# pse84 register map
Vendor: Cypress Semiconductor; Series: PSE84; File version: 1.0
CPU: CM33 r0p1, little endian, MPU, FPU, VTOR, 3 interrupt priority bits
Registers are 32-bit, read-write, reset 0x0 unless marked. A register's access mark holds for its fields unless they carry their own. Offsets are from the block's base; [hi:lo] are bit positions; lines under a group give offsets from that group; {n}, {i} and the like mark numbered series; 'fields as' and 'values as' point back to an identical list; <NAME> marks a mode.

## SMIF0 (part 3 of 4) — SMIF subsystem (bridge + 2 core SMIFs, OR no bridge and 1 core SMIF)
Base 0x44400000
{0x20000+0x20000*i} CORE[{i}] (i=0..1) group — Serial Memory Interface
  {0x800+0x80*j} DEVICE[{j}] (j=0..3) group — Device (only used for XIP acceses)
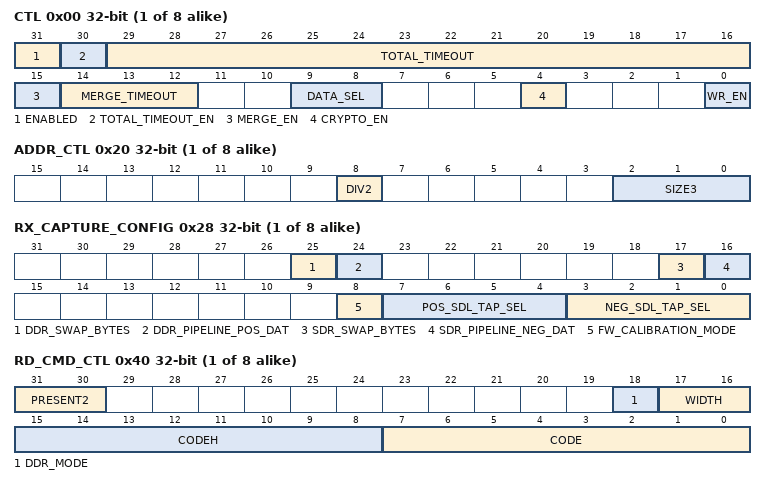
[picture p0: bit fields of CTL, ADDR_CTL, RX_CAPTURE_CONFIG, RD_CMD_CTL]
    0x00 CTL — Control
      [31] ENABLED — Device enable: '0': Disabled. '1': Enabled.
      [30] TOTAL_TIMEOUT_EN — Total transfer timeout enable. '0': Disabled. There is no limit for the total transfer time. The continuous transfer merge timeout for limiting the idle time of the memory interface still applies. '1': Enabled. The maximum total transfer time is limited by field TOTAL_TIMEOUT.
      [29:16] TOTAL_TIMEOUT — Total transfer timeout in clk_mem cycles. The counting of the total timout period is done in the XIP block using clk_mem cycles. It starts when the first command of a new (not merged) transaction is transferred to the TX command FIFO causing the interface logic to select the memory. After this period the memory device is deselected. This feature is needed for RAM devices requiring refresh cycles. The value needs to be derived from the RAMs maximum transaction length time (tCMS) minus the time of transferring 2x16byte data block (data granularity of the XIP ports is 16byte, 1 16byte block transfer outstanding, another available for merging). If the result in negative, MERGE_EN must be set to '0'. Example: RAM device tCMS = 4us, interface clock frequency = 100MHz: total transfer timeout is 4us - 2x16x10ns = 3680ns. With clk_mem frequency of 200MHz the TOTAL_TIMEOUT value is 3680/5 = 736. Note: In the unlikely case that the total transfer timeout is used (usually for RAM devices) while the page boundary crossing latency generation is enabled via RD_BOUND_CTL.PRESENT (usually for FLASH devices) the additional time needs to taken into account.
      [15] MERGE_EN — Continous transfer merge enable: '0': Disabled. No merging of transfers is done. Longest possible memory transfer is 16 Byte. '1': Enabled. Merging of continous transfers is done. This skips the overhead (command, address, mode, dummy cycles) for a continuous (linear sequential) transfer.
      [14:12] MERGE_TIMEOUT — Continuous transfer merge timeout in clk_mem cycles. This limits the standby time of the memory interface, i.e. the time the memory device is selected but no data is transferred. The counting of the merge timeout period is done in the XIP block using clk_mem cycles. It starts when the last TX or RX byte is transferred to or from the data FIFOs. After this period the memory device is deselected. A later transfer, even from a continuous address, starts with the overhead phases (command, address, mode, dummy cycles).
        0=_1_cycle (Timeout after 1 clk_mem cycle. That means transfers will only be merged if the continuous transfer request is already available when the previous transfer is finished.); 1=_16_cycles (Timeout after 2^4 = 16 clk_mem cycles. At a clk_mem frequency of 200MHz this means 80ns.); 2=_256_cycles (Timeout after 2^8 = 256 clk_mem cycles. At a clk_mem frequency of 200MHz this means ~1.3us.); 3=_4096_cycles (Timeout after 2^12 = 4096 clk_mem cycles. At a clk_mem frequency of 200MHz this means ~20us.); 4=_65536_cycles (Timeout after 2^16 = 65536 clk_mem cycles. At a clk_mem frequency of 200MHz this means ~330us.); 5=RSVD5 (N/A); 6=RSVD6 (N/A); 7=RSVD7 (N/A)
      [9:8] DATA_SEL — Specifies the connection of the IP's data lines (spi_data[0], ..., spi_data[7]) to the device's data lines (SI/IO0, SO/IO1, IO2, IO3, IO4, IO5, IO6, IO7): '0': spi_data[0] = IO0, spi_data[1] = IO1, ..., spi_data[7] = IO7. This value is allowed for single, dual, quad, dual quad and octal SPI modes. This value must be used for the first device in dual quad SPI mode. This value must be used for octal SPI mode. '1': spi_data[2] = IO0, spi_data[3] = IO1. This value is only allowed for single and dual SPI modes. '2': spi_data[4] = IO0, spi_data[5] = IO1, ..., spi_data[7] = IO3. This value is only allowed for single, dual, quad and dual quad SPI modes. In dual quad SPI mode, this value must be used for the second device. '3': spi_data[6] = IO0, spi_data[7] = IO1. This value is only allowed for single and dual SPI modes.
      [4] CRYPTO_EN — Cryptography on read/write accesses: '0': disabled. '1': enabled. This register should not be changed dynamically. Conditions 1. The same CRYPTO_EN setting should be used when a memory is read back after a write. 2. CRYPTO_EN should not be changed while IP is busy.
      [0] WR_EN — Write enable: '0': write transfers are not allowed to this device. An attempt to write to this device results in an AHB-Lite bus error. '1': write transfers are allowed to this device.
    0x08 ADDR reset not defined — Device region base address
      [31:8] ADDR — Specifies the base address of the device region. If the device region is 2^m Bytes, ADDR MUST be a multiple of 2^m. In dual quad SPI data transfer, the two devices should have the same ADDR and MASK register settings. The device control information (ADDR_CTL, RD_CMD_CTL, etc.) are provided by the MMIO control registers of the device with the lowest index. The most significant bit fields are constants and set based on the SMIF_XIP_ADDR parameter. The most significant bits are identified on the SMIF_XIP_MASK parameter. E.g., if SMIF_XIP_MASK is 0xff00:0000 (16 MB XIP memory region), ADDR[31:24] = SMIF_XIP_ADDR[31:24].
    0x0C MASK reset not defined — Device region mask
      [31:8] MASK — Specifies the size of the device region. All '1' bits are used to compare the incoming transfer request address A[31:0] with the address as specified in ADDR.ADDR: Address A is in the device when (A[31:8] & MASK[31:8]) == ADDR.ADDR[31:8]. The most significant bit fields are constants and set to'1'. The most significant bits are identified on the SMIF_XIP_MASK parameter. E.g., if SMIF_XIP_MASK is 0xff00:0000 (16 MB XIP memory region), MASK[31:24] = 0xff. Note: a transfer request that is not in any device region results in an AHB-Lite bus error.
    0x20 ADDR_CTL — Address control
      [8] DIV2 — Specifies if the AHB-Lite bus transfer address is divided by 2 or not: '0': No divide by 2. '1': Divide by 2. This functionality is used for read and write operation in XIP, dual quad SPI mode; i.e. this DIV2 must be set to '1' in dual quad SPI mode. If DIV2 is set to '1', the memory does not support write masking (WR_DUMMY_CTL.RWDS_EN = '0'), and in this configuration a write transfer is requested and the write transfer request address is NOT a multiple of 2 or the requested number of Bytes to be written is not a multiple of 2, the XIP_ALIGNMENT_ERROR interrupt cause is activated.
      [2:0] SIZE3
    0x28 RX_CAPTURE_CONFIG — RX capture configuration
      [25] DDR_SWAP_BYTES — 0: Does not swap DDR receive data captured relative to the negedge of the receive clock with the data captured relative to the posedge of the receive clock 1: Does swap The setting DDR_SWAP_BYTES is ignored and operates as if set to 1 (even if set to 0) when CORE.CTL2.RX_CAPTURE_MODE=2
      [24] DDR_PIPELINE_POS_DAT — 0: Does not pipeline DDR receive data captured relative to the posedge of the receive clock 1: Does pipeline DDR_PIPELINE_POS_DAT must be set to '1' if CORE.CTL2.RX_CAPTURE_MODE=2
      [17] SDR_SWAP_BYTES — 0: Does not swap SDR receive data captured relative to the negedge of the receive clock with the data captured relative to the posedge of the receive clock 1: Does swap
      [16] SDR_PIPELINE_NEG_DAT — 0: Does not pipeline SDR receive data captured relative to the negedge of the receive clock 1: Does pipeline
      [8] FW_CALIBRATION_MODE — 0: Disabled 1: Enabled Hyperbus / xSPI / Octal SPI w/DQS and Software De-skewing Mode based on register HB FW Calibration tap sel0/1
      [7:4] POS_SDL_TAP_SEL — Same as NEG_SDL_TAP_SEL except for the 'pos' SDL.
      [3:0] NEG_SDL_TAP_SEL — Determines the amount of delay through the 'neg' SDL for the receive clock coming from the pins in terms of the number of tap delays. There are 16 SDL taps and the delay resolution of each tap is controlled by and thus closely mimics the delay resolution of the MDL. i.e., each tap has a resolution roughly equal to 1/16th of the DLL reference clock period. Setting 0 constitutes 1 tap delay, setting 1 constitutes 2 tap delays, etc., setting 15 constitutes 16 tap delays (effectively a full DLL reference clock period).
    0x30 RD_STATUS ro — Read status
      [7:0] FS_STATUS — Provides the Functional Safety Status Register of the memory received with the last read transfer.
    0x40 RD_CMD_CTL — Read command control
      [31:30] PRESENT2 — Presence of command field: '0': not present '1': present (1 Byte) '2': present (2 Byte for OPI) Note: For octal data transfer with DDR mode (WIDTH='3' and DDR_MODE='1') either the HB protocol needs to be selected (by ADDR_CTL.SIZE3='7') or this field needs to be set to PRESENT2='2'.
      [18] DDR_MODE — Mode of transfer rate: '0': SDR mode '1': DDR mode
      [17:16] WIDTH — Width of data transfer: '0': 1 bit/cycle (single data transfer). '1': 2 bits/cycle (dual data transfer). '2': 4 bits/cycle (quad data transfer). '3': 8 bits/cycle (octal data transfer).
      [15:8] CODEH — Command high byte code. This field specifies the most significant command byte, sent before the least significant command byte (CODE). It is only used when PRESENT2 = '2'.
      [7:0] CODE — Command byte code.
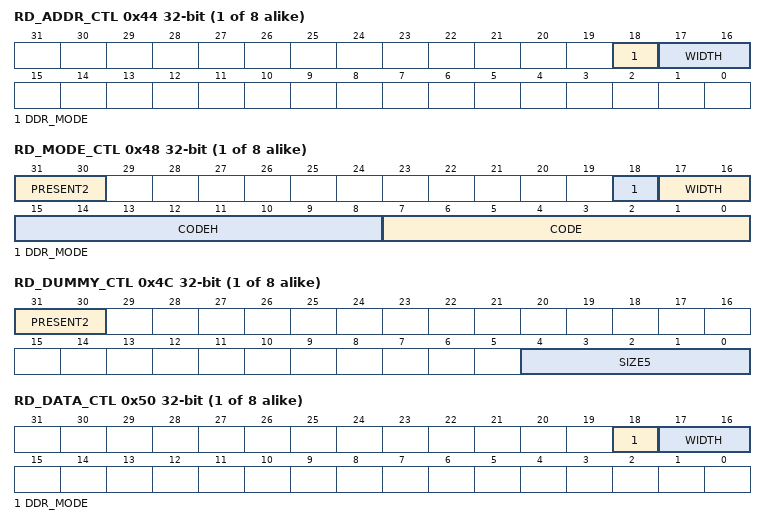
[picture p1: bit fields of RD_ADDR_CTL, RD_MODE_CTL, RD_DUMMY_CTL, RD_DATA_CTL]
    0x44 RD_ADDR_CTL — Read address control
      [18] DDR_MODE — Mode of transfer rate.
      [17:16] WIDTH — Width of transfer.
    0x48 RD_MODE_CTL — Read mode control
      [31:30] PRESENT2 — Presence of mode field: '0': not present '1': present (1 Byte) '2': present (2 Byte for OPI) Note: For octal data transfer with DDR mode (WIDTH='3' and DDR_MODE='1') this field needs to be set to PRESENT2='2' to generate a mode field (or to PRESENT2='0').
      [18] DDR_MODE — Mode of transfer rate.
      [17:16] WIDTH — Width of transfer.
      [15:8] CODEH — Mode high byte code. This field specifies the most significant mode byte, sent before the least significant mode byte (CODE). It is only used when PRESENT2 = '2'.
      [7:0] CODE — Mode byte code. Note: If a mode field is present (PRESENT='1') for octal data transfer with DDR mode (WIDTH='3' and DDR_MODE='1') the CODE is sent twice.
    0x4C RD_DUMMY_CTL — Read dummy control
      [31:30] PRESENT2 — Presence of dummy cycles: '0': not present '1': present '2': present - Dummy cycles are doubled when RWDS refresh indicator is high during CA cycle. (HyperRAM variable latency mode) Notes: - If transmitting command, address and mode fields in SDR mode (driving data between falling edges of spihb_clk_out) and the memory is driving read data in DDR mode (based on memory type and transmitted command), then there must be at least 1 latency / dummy cycle specified (RD_DUMMY_CTL.PRESENT2 > 0') to prevent controller and memory driving data signals at the same time. The same is true for the theoretical (practically irrelevant case) of transmitting at least one of the command, address and mode fields in DDR mode but receiving data from the memory in SDR mode. - When using the RWDS / DQS based capturing scheme (CTL2.RX_CAPTURE_MODE = 2), then there is a minimum number of latency / dummy cycles required (RD_DUMMY_CTL.PRESENT2 > 0). For the Hyperbus protocol (DDR_CTL.SIZE3=7) at least 1 latency / dummy cycle has to be specified, for SPI with DQS capturing at least 2 latency / dummy cycles need to be selected (RD_DUMMY_CTL.SIZE5 > 0, exception see following note). - In case of falling edge RWDS / DQS capturing (CTL2.RX_CAPTURE_MODE = 2) and SDR mode, SW should reduce the number of dummy cycles by 1 compared to the latency cycles required by the memory device. -DDR read commands need at least one dummy cycle -For Hyperbus, set RD DUMMY_CTL.SIZE5=initial latency cycles-2
      [4:0] SIZE5 — Number of dummy cycles (minus 1): '0': 1 cycles ... '31': 32 cycles. Note: this field specifies dummy cycles, not dummy Bytes!
    0x50 RD_DATA_CTL — Read data control
      fields as CORE[0].DEVICE[0].RD_ADDR_CTL
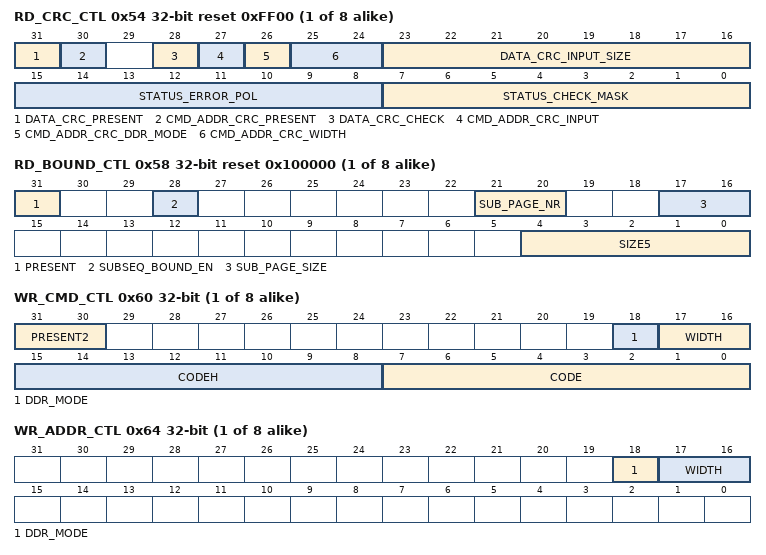
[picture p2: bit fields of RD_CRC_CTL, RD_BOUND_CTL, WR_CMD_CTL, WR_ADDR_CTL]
    0x54 RD_CRC_CTL reset 0xFF00 — Read Bus CRC control
      [31] DATA_CRC_PRESENT — Presence of data CRC field: '0': not present '1': present Note: Width and data transfer mode (SDR or DDR) of read data CRC fields are the same as for the associated read data fields, i.e. are specified by RD_DATA_CTL.WIDTH and RD_DATA_CTL.DDR_MODE.
      [30] CMD_ADDR_CRC_PRESENT — Presence of command / address CRC field: '0': not present '1': present Note: For octal data transfer with DDR mode (RD_CRC_CTL.WIDTH='3' and RD_CRC_CTL.DDR_MODE='1') the command / address CRC byte is sent twice, otherwise the command / address CRC byte is only sent once.
      [28] DATA_CRC_CHECK
      [27] CMD_ADDR_CRC_INPUT — Specifies which fields are included in the command / address CRC generation. '0': The command / address CRC field is generated over the address and (if present) mode fields only. '1': The command / address CRC field is generated over the command, address and (if present) mode fields.
      [26] CMD_ADDR_CRC_DDR_MODE — Mode of transfer rate of command / address CRC field.
      [25:24] CMD_ADDR_CRC_WIDTH — Width of command / address CRC field.
      [23:16] DATA_CRC_INPUT_SIZE — Number of input data bytes for CRC generation (minus 1), i.e. number of data bytes over which the data CRC field is generated (minus 1): '0': 1 byte ... '255': 256 bytes. Note: For octal data transfer with DDR mode (RD_DATA_CTL.WIDTH='3' and RD_DATA_CTL.DDR_MODE='1') the number of bytes for CRC generation must be even (i.e. DATA_CRC_INPUT_SIZE must be odd).
      [15:8] STATUS_ERROR_POL — Specifies the polarity of the Functional Safety Status field bits. There is 1 polarity bit for each Functional Safety Status bit. '0': The associated Functional Safety Status bit is active-low. '1': The associated Functional Safety Status bit is active-high.
      [7:0] STATUS_CHECK_MASK — Specifies which of the Functional Safety Status field bits are checked. There is 1 mask bit for each Functional Safety Status bit. '0': The associated Functional Safety Status bit is not checked. '1': The associated Functional Safety Status bit is checked. If the received Funciontal Safety Status bit = Functional Safety Status Error Polarity (STATUS_ERROR_POLARITY), then a Functional Safety Status error interrupt and a XIP bus error response is generated.
    0x58 RD_BOUND_CTL reset 0x100000 — Read boundary control
      [31] PRESENT — Presence of first page boundary latency cycles: '0': not present '1': present
      [28] SUBSEQ_BOUND_EN — Enable subsequent page boundary latency cycles. '0': Disabled. The page crossing latency cycles are only generated when crossing the first page boundary (i.e. the first time when the SUB_PAGE_NRth sub page boundary is crossed, e.g. with 2 sub pages per page when the 2nd sub page boundary is crossed). '1': Enabled. The page crossing latency cycles are generated when crossing the first and subsequent page boundaries (i.e. every time when a SUB_PAGE_NRth sub page boundary is crossed, e.g. with 2 sub pages per page when the 2nd, 4th, 6th, ... sub page boundary is crossed). Note: This only applies when the number of base latency cycles (SIZE5+1) is greater than the size of a page (base_latency > page_size). Must be set to 0 otherwise.
      [21:20] SUB_PAGE_NR — Specifies the number of sub pages per page. '0': 1 sub pages per page, i.e. page_size = sub_page_size '1': 2 sub pages per page, i.e. page_size = 2 x sub_page_size '2': 4 sub pages per page, i.e. page_size = 4 x sub_page_size '3': 8 sub pages per page, i.e. page_size = 8 x sub_page_size
      [17:16] SUB_PAGE_SIZE — Specifies the size of a memory sub page 'sub_page_size'. '0': sub_page_size = 8 words = 16 bytes (default). '1': sub_page_size = 16 words = 32 bytes. '2': sub_page_size = 32 words = 64 bytes. '3': sub_page_size = 64 words = 128 bytes.
      [4:0] SIZE5 — Number of base latency cycles (minus 1) used for calculating the number of fist page boundary crossing latency cycles: '0': base_latency = 1 cycles ... '31': base_latency = 32 cycles. The actual latency cycles when crossing the first page boundary depend on the start address of the transaction and is calculated as follows: if ((page_size - base_latency) < Start_Addr & (sub_page_size - 1)) { ((Start_Addr & (sub_page_size - 1)) - page_size + base_latency) } else { 0 }
    0x60 WR_CMD_CTL — Write command control
      [31:30] PRESENT2 — Presence of command field: '0': not present '1': present (1 Byte) '2': present (2 Byte for OPI) Note: For octal data transfer with DDR mode (WIDTH='3' and DDR_MODE='1') either the HB protocol needs to be selected (by ADDR_CTL.SIZE3='7') or this field needs to be set to PRESENT2='2'.
      [18] DDR_MODE — Mode of transfer rate.
      [17:16] WIDTH — Width of transfer.
      [15:8] CODEH — Command high byte code. This field specifies the most significant command byte, sent before the least significant command byte (CODE). It is only used when PRESENT2 = '2'.
      [7:0] CODE — Command byte code.
    0x64 WR_ADDR_CTL — Write address control
      fields as CORE[0].DEVICE[0].RD_ADDR_CTL
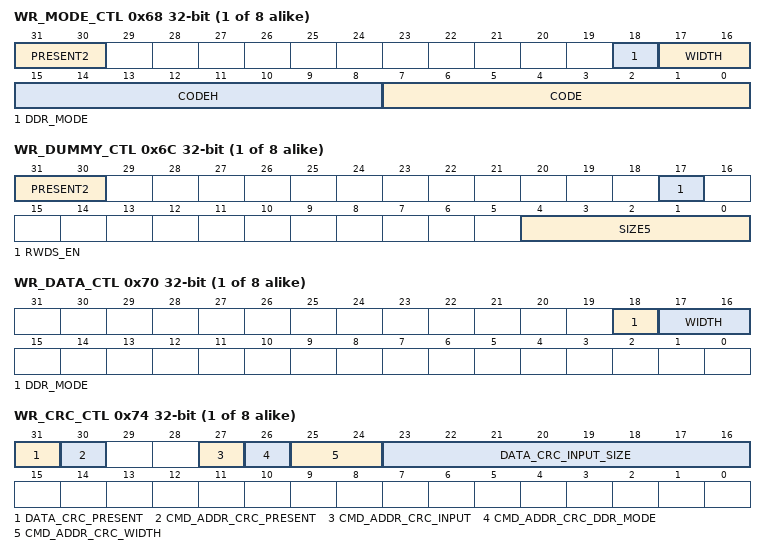
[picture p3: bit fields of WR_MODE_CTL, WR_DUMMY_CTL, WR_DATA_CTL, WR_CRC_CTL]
    0x68 WR_MODE_CTL — Write mode control
      [31:30] PRESENT2 — Presence of mode field: '0': not present '1': present (1 Byte) '2': present (2 Byte for OPI) Note: For octal data transfer with DDR mode (WIDTH='3' and DDR_MODE='1') this field needs to be set to PRESENT2='2' to generate a mode field (or to PRESENT2='0').
      [18] DDR_MODE — Mode of transfer rate.
      [17:16] WIDTH — Width of transfer.
      [15:8] CODEH — Mode high byte code. This field specifies the most significant mode byte, sent before the least significant mode byte (CODE). It is only used when PRESENT2 = '2'.
      [7:0] CODE — Mode byte code.
    0x6C WR_DUMMY_CTL — Write dummy control
      [31:30] PRESENT2 — Presence of dummy cycles: '0': not present '1': present '2': present - Dummy cycles are doubled when RWDS refresh indicator is high during CA cycle. (HyperRAM variable latency mode)
      [17] RWDS_EN — Read-Write-Data-Strobe Enable. Specifies whether the RWDS output signal should be driven starting in the last dummy cycle until DESELECT. This is needed for write transactions with byte masking via RWDS (e.g. Hyperbus). '0': do not drive RWDS output '1': drive RWDS output starting in last dummy cycle until DESELECT Note: this field is located in the WR_DUMMY_CTL register (and not in the WR_DATA_CTL register) since the RWDS signal needs to be driven already in the last dummy cycle.
      [4:0] SIZE5 — Number of dummy cycles (minus 1): '0': 1 cycles ... '31': 32 cycles.
    0x70 WR_DATA_CTL — Write data control
      fields as CORE[0].DEVICE[0].RD_ADDR_CTL
    0x74 WR_CRC_CTL — Write Bus CRC control
      [31] DATA_CRC_PRESENT — Presence of data CRC field: '0': not present '1': present Note: Width and data transfer mode (SDR or DDR) of read data CRC fields are the same as for the associated read data fields, i.e. are specified by RD_DATA_CTL.WIDTH and RD_DATA_CTL.DDR_MODE. Note: For octal data transfer with DDR mode (RD_DATA_CTL.WIDTH='3' and RD_DATA_CTL.DDR_MODE='1') the data CRC byte is sent twice, otherwise the data CRC byte is only sent once.
      [30] CMD_ADDR_CRC_PRESENT — Presence of command / address CRC field: '0': not present '1': present Note: For octal data transfer with DDR mode (RD_CRC_CTL.WIDTH='3' and RD_CRC_CTL.DDR_MODE='1') the command / address CRC byte is sent twice, otherwise the command / address CRC byte is only sent once.
      [27] CMD_ADDR_CRC_INPUT — Specifies which fields are included in the command / address CRC generation. '0': The command / address CRC field is generated over the address and (if present) mode fields only. '1': The command / address CRC field is generated over the command, address and (if present) mode fields.
      [26] CMD_ADDR_CRC_DDR_MODE — Mode of transfer rate of command / address CRC field.
      [25:24] CMD_ADDR_CRC_WIDTH — Width of command / address CRC field.
      [23:16] DATA_CRC_INPUT_SIZE — Number of input data bytes for CRC generation (minus 1), i.e. number of data bytes over which the data CRC field is generated (minus 1): '0': 1 byte ... '255': 256 bytes. Note: For octal data transfer with DDR mode (WR_DATA_CTL.WIDTH='3' and WR_DATA_CTL.DDR_MODE='1') the number of bytes for CRC generation must be even (i.e. DATA_CRC_INPUT_SIZE must be odd).
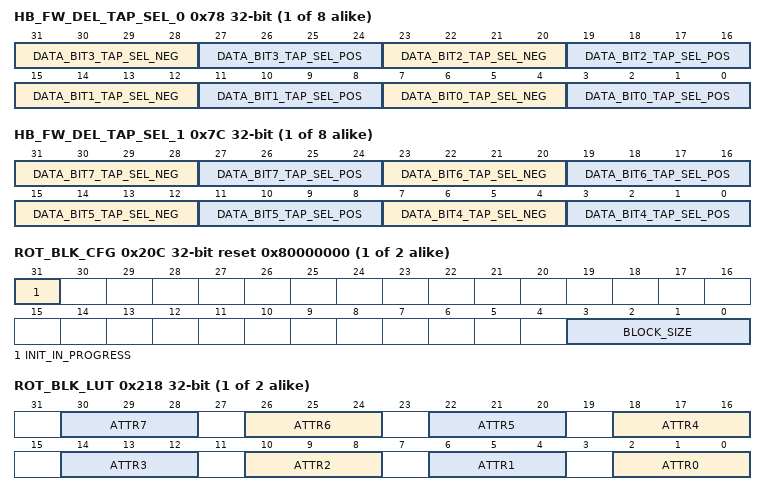
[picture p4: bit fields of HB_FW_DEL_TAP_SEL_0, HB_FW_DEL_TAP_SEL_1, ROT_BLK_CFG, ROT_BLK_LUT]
    0x78 HB_FW_DEL_TAP_SEL_0 — HB FW Calibration Delay Tap Select 0
      [31:28] DATA_BIT3_TAP_SEL_NEG — HB FW Calibration: Delay line tap select for spi_data[3], NEG Clock Phase (note the mapping of spi_data to IO in DEVICE.CTL.DATA_SEL). See DATA_BIT0_TAP_SEL.
      [27:24] DATA_BIT3_TAP_SEL_POS — HB FW Calibration: Delay line tap select for spi_data[3], POS Clock Phase (note the mapping of spi_data to IO in DEVICE.CTL.DATA_SEL). See DATA_BIT0_TAP_SEL.
      [23:20] DATA_BIT2_TAP_SEL_NEG — HB FW Calibration: Delay line tap select for spi_data[2], NEG Clock Phase (note the mapping of spi_data to IO in DEVICE.CTL.DATA_SEL). See DATA_BIT0_TAP_SEL.
      [19:16] DATA_BIT2_TAP_SEL_POS — HB FW Calibration: Delay line tap select for spi_data[2], POS Clock Phase (note the mapping of spi_data to IO in DEVICE.CTL.DATA_SEL). See DATA_BIT0_TAP_SEL.
      [15:12] DATA_BIT1_TAP_SEL_NEG — HBs FW Calibration: Delay line tap select for spi_data[1], NEG Clock Phase (note the mapping of spi_data to IO in DEVICE.CTL.DATA_SEL). See DATA_BIT0_TAP_SEL.
      [11:8] DATA_BIT1_TAP_SEL_POS — HB FW Calibration: Delay line tap select for spi_data[1], POS Clock Phase (note the mapping of spi_data to IO in DEVICE.CTL.DATA_SEL). See DATA_BIT0_TAP_SEL.
      [7:4] DATA_BIT0_TAP_SEL_NEG — HB FW Calibration: Delay line tap select for spi_data[0], NEG Clock Phase (note the mapping of spi_data to IO in DEVICE.CTL.DATA_SEL). See DATA_BIT0_TAP_SEL.
      [3:0] DATA_BIT0_TAP_SEL_POS — HB FW Calibration tap select for spi_data[0], POS clock Phase (note the mapping of spi_data to IO in DEVICE.CTL.DATA_SEL).
    0x7C HB_FW_DEL_TAP_SEL_1 — HB FW Calibration Delay Tap Select 1
      [31:28] DATA_BIT7_TAP_SEL_NEG — HB FW Calibration: Delay line tap select for spi_data[7], NEG Clock Phase (note the mapping of spi_data to IO in DEVICE.CTL.DATA_SEL). See DATA_BIT0_TAP_SEL.
      [27:24] DATA_BIT7_TAP_SEL_POS — HB FW Calibration: Delay line tap select for spi_data[7], POS Clock Phase (note the mapping of spi_data to IO in DEVICE.CTL.DATA_SEL). See DATA_BIT0_TAP_SEL.
      [23:20] DATA_BIT6_TAP_SEL_NEG — HB FW Calibration: Delay line tap select for spi_data[6], NEG Clock Phase (note the mapping of spi_data to IO in DEVICE.CTL.DATA_SEL). See DATA_BIT0_TAP_SEL.
      [19:16] DATA_BIT6_TAP_SEL_POS — HB FW Calibration: Delay line tap select for spi_data[6], POS Clock Phase (note the mapping of spi_data to IO in DEVICE.CTL.DATA_SEL). See DATA_BIT0_TAP_SEL.
      [15:12] DATA_BIT5_TAP_SEL_NEG — HBs FW Calibration: Delay line tap select for spi_data[5], NEG Clock Phase (note the mapping of spi_data to IO in DEVICE.CTL.DATA_SEL). See DATA_BIT0_TAP_SEL.
      [11:8] DATA_BIT5_TAP_SEL_POS — HB FW Calibration: Delay line tap select for spi_data[5], POS Clock Phase (note the mapping of spi_data to IO in DEVICE.CTL.DATA_SEL). See DATA_BIT0_TAP_SEL.
      [7:4] DATA_BIT4_TAP_SEL_NEG — HB FW Calibration: Delay line tap select for spi_data[4], NEG Clock Phase (note the mapping of spi_data to IO in DEVICE.CTL.DATA_SEL). See DATA_BIT0_TAP_SEL.
      [3:0] DATA_BIT4_TAP_SEL_POS — HB FW Calibration tap select for spi_data[4], POS clock Phase (note the mapping of spi_data to IO in DEVICE.CTL.DATA_SEL).
  0x1000 SLOW_AHB group — Serial Memory Interface
    0x00 MPC group — MPC Memory Protection Controller registers
      0x00 CFG — Config register with error response, RegionID PPC_MPC_MAIN is the security owner PC. The error response configuration is located in CFG.RESPONSE, only one such configuration exists applying to all protection contexts in the system.
        [4] RESPONSE — Response Configuration for Security and PC violations 0: Read-Zero Write Ignore (RAZ/WI) 1: Bus Error
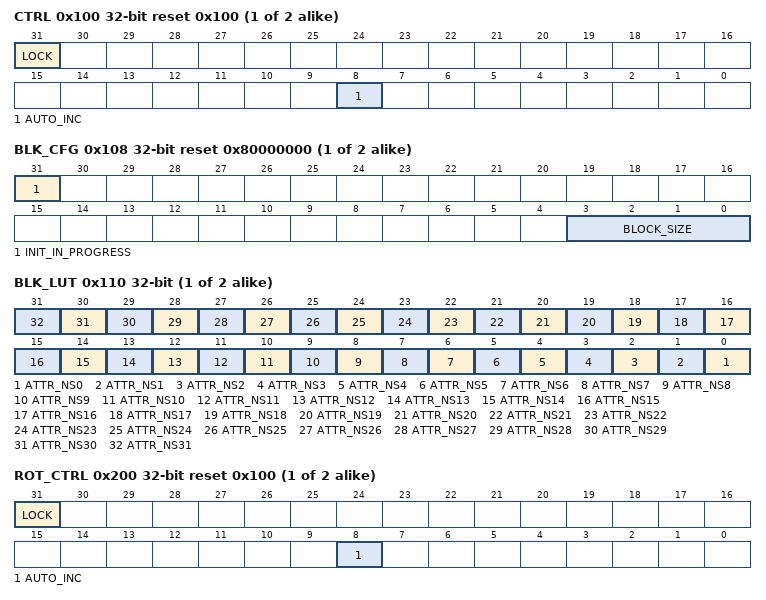
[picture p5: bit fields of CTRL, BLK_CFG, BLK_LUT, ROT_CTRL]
      0x100 CTRL reset 0x100 — Control register with lock bit and auto-increment only (Separate CTRL for each PC depends on access_pc)
        [31] LOCK — Security lockdown for this protection context. Software can set this bit but not clear it once set. When set, write operations to BLK_LUT are not possible from this protection context. Setting LOCK also blocks writes to CTRL itself (for that PC copy). All writes are ignored.
        [8] AUTO_INC — Auto-increment BLK_IDX by 1 for this protection context as a side effect of each read/write access to BLK_LUT
      0x104 BLK_MAX ro — Max value of block-based index register
        [31:0] VALUE — Maximum value of block-based index register. The number and size blocks in an MPC is design time configurable and for embedded memories defaults to covering the entire memory using 4kB blocks; See product datasheet for details on protection of external memories.
      0x108 BLK_CFG ro reset 0x80000000 — Block size & initialization in progress
        [31] INIT_IN_PROGRESS — During initialization INIT_IN_PROGRESS is '1' and MMIO register accesses to BLK_LUT is blocked (BLK_IDX increment is also ignored). The block attributes are retained in DeepSleep (and obviously Active) power mode. Initialization is only required from a power mode in which the block attributes are not retained. E.g., initialization is required for a cold boot (after a Power-on-Reset). HW initializes the block attributes: the NS attributes are set to '0' (secure), the R attributes are set to '1' (read access allowed) and the W attributes are set to '1' (write access allowed). During initialization, the MPC supports memory accesses (memory accesses are NOT blocked) with the initialization block attribute values as mentioned above. This e.g. allows MPC initialization to proceed in parallel with boot program memory accesses (as opposed to serializing the two), improving device boot time.
        [3:0] BLOCK_SIZE — Block size of individually protected blocks (0: 32B, 1: 64B, ... up to 15: 1MB) Block size= (1<<(BLOCK_SIZE+5)) The number and size blocks in an MPC is design time configurable and for embedded memories defaults to covering the entire memory using 4kB blocks; see product datasheet for details on protection of external memories.
      0x10C BLK_IDX — Index of 32-block group accessed through BLK_LUT (Separate IDX for each PC depending on access_pc)
        [31:0] VALUE — Index value for accessing block-based lookup table using BLK_LUT. Programming out of LUT range is an user error and it loops back to '0' once overflow occurs.
      0x110 BLK_LUT — NS status for 32 blocks at BLK_IDX with PC=<access_pc>
        [n] ATTR_NS{n} (n=0..31) — NS bit for block {n} based on BLK_IDX
      0x200 ROT_CTRL reset 0x100 — Control register with lock bit and auto-increment only
        [31] LOCK — Security lockdown for the root-of-trust configuration registers. Software can set this bit but not clear it once set. When set, write operations to ROT_BLK_LUT are not possible. Write is ignored.
        [8] AUTO_INC — Auto-increment BLK_IDX by 1 for each read/write of ROT_BLK_LUT
      0x208 ROT_BLK_MAX ro — Max value of block-based index register for ROT
        [31:0] VALUE — Maximum value of block-based index register. The number and size blocks in an MPC is design time configurable and for embedded memories defaults to covering the entire memory using 4kB blocks; see product datasheet for details on protection of external memories.
      0x20C ROT_BLK_CFG ro reset 0x80000000 — Same as BLK_CFG
        [31] INIT_IN_PROGRESS — During initialization INIT_IN_PROGRESS is '1' and MMIO register accesses to ROT_BLK_LUT is RAZWI. The block attributes are retained in DeepSleep (and obviously Active) power mode. Initialization is only required from a power mode in which the block attributes are not retained. E.g., initialization is required for a cold boot (after a Power-on-Reset). HW initializes the block attributes: the NS attributes are set to '0' (secure), the R attributes are set to '1' (read access allowed) and the W attributes are set to '1' (write access allowed). During initialization, the MPC supports memory accesses (memory accesses are NOT blocked) with the initialization block attribute values as mentioned above. This e.g. allows MPC initialization to proceed in parallel with boot program memory accesses (as opposed to serializing the two), improving device boot time.
        [3:0] BLOCK_SIZE — Block size of individually protected blocks (0: 32B, 1: 64B, ...up to 15:1MB) Block size= (1<<(BLOCK_SIZE+5)) The number and size blocks in an MPC is design time configurable and for embedded memories defaults to covering the entire memory using 4kB blocks; see product datasheet for details on protection of external memories.
      0x210 ROT_BLK_IDX — Index of 8-block group accessed through ROT_BLK_LUT_*
        [31:0] VALUE — Index value for accessing block-based lookup table using ROT_BLK_LUT. Programming out of LUT range is an user error and it loops back to '0' once overflow occurs.
      0x214 ROT_BLK_PC — Protection context of 8-block group accesses through ROT_BLK_LUT
        [3:0] PC — Specify PC values for ROT_BLK_IDX and ROT_BLK_LUT
      0x218 ROT_BLK_LUT — (R,W,NS) bits for 8 blocks at ROT_BLK_IDX for PC=ROT_BKL_PC
        [4n+2:4n] ATTR{n} (n=0..7) — W/R/NS bits for block {n} indicated by ROT_BLK_IDX for ROT_BLK_PC PC
  0x2000 FAST_AHB group — Serial Memory Interface
    0x00 MPC group — MPC Memory Protection Controller registers
      0x00 CFG — Config register with error response, RegionID PPC_MPC_MAIN is the security owner PC. The error response configuration is located in CFG.RESPONSE, only one such configuration exists applying to all protection contexts in the system.
        fields as CORE[0].SLOW_AHB.MPC.CFG
      0x100 CTRL reset 0x100 — Control register with lock bit and auto-increment only (Separate CTRL for each PC depends on access_pc)
        fields as CORE[0].SLOW_AHB.MPC.CTRL
      0x104 BLK_MAX ro — Max value of block-based index register
        fields as CORE[0].SLOW_AHB.MPC.BLK_MAX
      0x108 BLK_CFG ro reset 0x80000000 — Block size & initialization in progress
        fields as CORE[0].SLOW_AHB.MPC.BLK_CFG
      0x10C BLK_IDX — Index of 32-block group accessed through BLK_LUT (Separate IDX for each PC depending on access_pc)
        fields as CORE[0].SLOW_AHB.MPC.BLK_IDX
      0x110 BLK_LUT — NS status for 32 blocks at BLK_IDX with PC=<access_pc>
        [n] ATTR_NS{n} (n=0..31) — NS bit for block {n} based on BLK_IDX
      0x200 ROT_CTRL reset 0x100 — Control register with lock bit and auto-increment only
        fields as CORE[0].SLOW_AHB.MPC.ROT_CTRL
      0x208 ROT_BLK_MAX ro — Max value of block-based index register for ROT
        fields as CORE[0].SLOW_AHB.MPC.ROT_BLK_MAX
